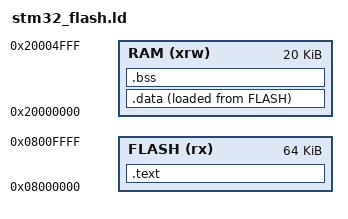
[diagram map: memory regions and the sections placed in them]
/* Đỉnh của ngăn xếp (Stack Top) = RAM_START + RAM_SIZE (20K = 0x5000) */
_estack = 0x20005000;

/* Khai báo dung lượng Flash và RAM cho STM32F103 Medium Density */
MEMORY
{
  FLASH (rx)      : ORIGIN = 0x08000000, LENGTH = 64K
  RAM (xrw)       : ORIGIN = 0x20000000, LENGTH = 20K
}

/* Điểm bắt đầu chạy chương trình */
ENTRY(Reset_Handler)

SECTIONS
{
  .text :
  {
    KEEP(*(.isr_vector))
    *(.text)
    *(.text.*)
    *(.rodata)
    *(.rodata.*)
    . = ALIGN(4);
    _etext = .;
  } > FLASH

  _sidata = LOADADDR(.data);

  .data :
  {
    . = ALIGN(4);
    _sdata = .;
    *(.data)
    *(.data.*)
    . = ALIGN(4);
    _edata = .;
  } > RAM AT > FLASH

  .bss :
  {
    . = ALIGN(4);
    _sbss = .;
    *(.bss)
    *(.bss.*)
    *(COMMON)
    . = ALIGN(4);
    _ebss = .;
  } > RAM
}
